# mpc_me30 register map
Registers are read-only, no defined reset value unless marked. A register's access mark holds for its fields unless they carry their own. Offsets are from the block's base; lines under a group give offsets from that group; [hi:lo] are bit positions; {n}, {i} and the like mark numbered series; 'fields as' and 'values as' point back to an identical list; <NAME> marks a mode.

## Memory map
0x50091000 MPC size 0x1000 — Memory Protection Control.

## Interrupts
48 MPC

## MPC — Memory Protection Control.
Base 0x50091000
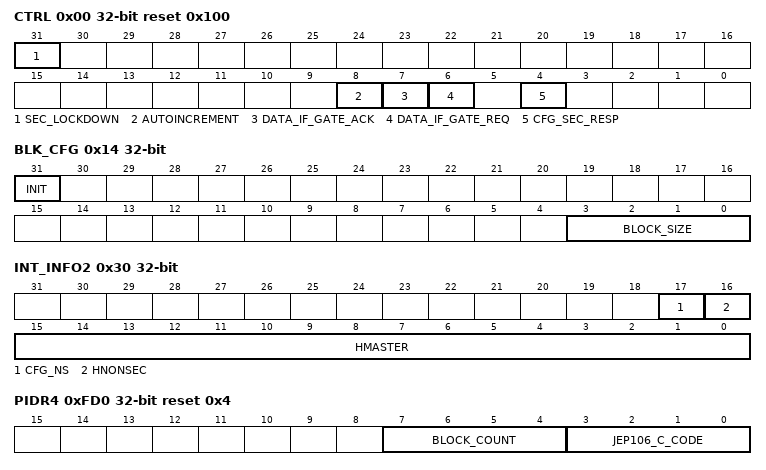
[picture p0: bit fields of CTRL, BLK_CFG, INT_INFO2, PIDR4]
0x00 CTRL access not given reset 0x100 — Control register.
  [31] SEC_LOCKDOWN — Security lockdown.
  [8] AUTOINCREMENT — Auto increment block index.
  [7] DATA_IF_GATE_ACK ro — Data interface gating acknowledge.
  [6] DATA_IF_GATE_REQ — Data interface gating request.
  [4] CFG_SEC_RESP — Security error response configuration.
    0=RAZ_WI (Read as zero or writes ignored.); 1=BUS_ERR (Bus error.)
0x10 BLK_MAX — Maximum value of block based index register.
  [31:0] IND_MAX — Maximum value.
0x14 BLK_CFG — Block configuration.
  [31] INIT — Initialization in progress.
  [3:0] BLOCK_SIZE
0x18 BLK_IDX access not given — Index value for accessing block based look up table.
  [31:0] INDEX — Index value.
0x1C BLK_LUTn access not given — Block based LUT. Access to block based look up configuration space pointed to by BLK_IDX.
  [31:0] BLOCK — Each bit indicates one block.
    0=SECURE; 1=NONSECURE
0x20 INT_STAT — Interrupt status register.
  [0] mpc_irq_fl — MPC interrupt triggered.
0x24 INT_CLEAR wo — Interrupt enable register.
  [0] mpc_irq_clr — MPC interrupt clear (cleared automatically).
0x28 INT_EN access not given reset 0x1 — Interrupt enable register.
  [0] mpc_irq_en — Enables interrupt output generation.
0x2C INT_INFO1 — First security violating address. Subsequent security violationg transfers are not captured in this register until mpc_irq is cleared.
  [31:0] HADDR — Security violating address.
0x30 INT_INFO2 — Additional control bits of the first security violating address.
  [17] CFG_NS — Non-secure.
  [16] HNONSEC — Non-secure transfer indicator.
  [15:0] HMASTER — Master identifier.
0x34 INT_SET access not given — Interrupt setting.
  [0] mpc_irq — Debug only. Sets mpc_irq triggered in INT_STAT regardless of mpc_irq being enabled or not.
0xFD0 PIDR4 reset 0x4 — Peripheral ID 4.
  [7:4] BLOCK_COUNT
  [3:0] JEP106_C_CODE — JEP106 continuation code.
{0xFC0+4i} PIDR{i} (i=5..7) — Peripheral ID {i}.
  [31:0] PID{i} — Not used.
0xFE0 PIDR0 reset 0x60 — Peripheral ID 0.
  [7:0] PART_NUMBER
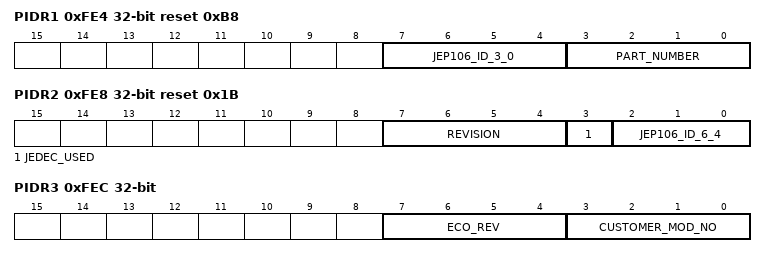
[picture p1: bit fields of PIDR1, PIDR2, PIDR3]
0xFE4 PIDR1 reset 0xB8 — Peripheral ID 1.
  [7:4] JEP106_ID_3_0 — Bits [3:0] of the JEDEC JEP106 Manufacturer ID code.
  [3:0] PART_NUMBER — Bits [11:8] of part number.
0xFE8 PIDR2 reset 0x1B — Peripheral ID 2.
  [7:4] REVISION
  [3] JEDEC_USED
  [2:0] JEP106_ID_6_4 — Bits [6:4] of the JEDEC JEP106 Manufacturer ID code.
0xFEC PIDR3 — Peripheral ID 3.
  [7:4] ECO_REV — ECO revision number.
  [3:0] CUSTOMER_MOD_NO — Customer modification number.
0xFF0 CIDR0 reset 0xD — Component ID 0.
  [31:0] CID0
0xFF4 CIDR1 reset 0xF0 — Component ID 1.
  [31:0] CID1 — Component ID 1 (PrimeCell class).
0xFF8 CIDR2 reset 0x5 — Component ID 2.
  [31:0] CID2
0xFFC CIDR3 reset 0xB1 — Component ID 3.
  [31:0] CID3
